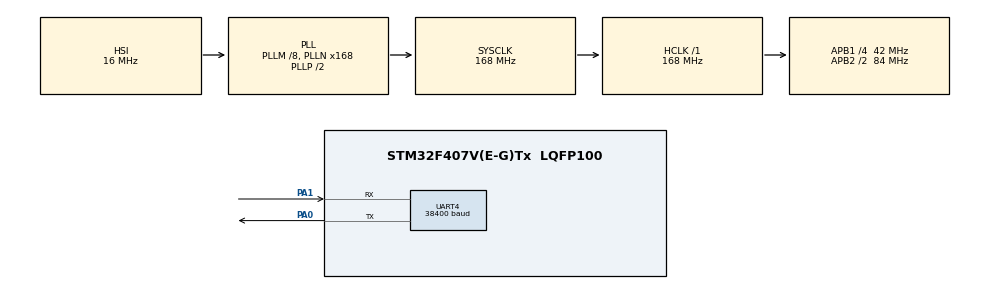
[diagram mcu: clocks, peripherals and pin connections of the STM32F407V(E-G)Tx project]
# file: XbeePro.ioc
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Mcu.Family=STM32F4
Mcu.Name=STM32F407V(E-G)Tx
Mcu.Package=LQFP100
NVIC.PriorityGroup=NVIC_PRIORITYGROUP_4
NVIC.UART4_IRQn=true\:0\:0\:false\:false\:true\:true\:true
PA0-WKUP.Mode=Asynchronous
PA0-WKUP.Signal=UART4_TX
PA1.Mode=Asynchronous
PA1.Signal=UART4_RX
PH0-OSC_IN.Mode=HSE-External-Oscillator
PH0-OSC_IN.Signal=RCC_OSC_IN
PH1-OSC_OUT.Mode=HSE-External-Oscillator
PH1-OSC_OUT.Signal=RCC_OSC_OUT
ProjectManager.HeapSize=0x200
ProjectManager.StackSize=0x400
ProjectManager.TargetToolchain=STM32CubeIDE
RCC.48MHZClocksFreq_Value=84000000
RCC.AHBFreq_Value=168000000
RCC.APB1CLKDivider=RCC_HCLK_DIV4
RCC.APB1Freq_Value=42000000
RCC.APB1TimFreq_Value=84000000
RCC.APB2CLKDivider=RCC_HCLK_DIV2
RCC.APB2Freq_Value=84000000
RCC.APB2TimFreq_Value=168000000
RCC.CortexFreq_Value=168000000
RCC.HCLKFreq_Value=168000000
RCC.HSE_VALUE=25000000
RCC.HSI_VALUE=16000000
RCC.LSE_VALUE=32768
RCC.PLLM=8
RCC.PLLN=168
RCC.SYSCLKFreq_VALUE=168000000
RCC.SYSCLKSource=RCC_SYSCLKSOURCE_PLLCLK
RCC.VCOOutputFreq_Value=336000000
UART4.BaudRate=38400
UART4.VirtualMode=Asynchronous
board=custom

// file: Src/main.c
/* USER CODE BEGIN Header */
/**
  ******************************************************************************
  * @file           : main.c
  * @brief          : Main program body
  ******************************************************************************
  * @attention
  *
  * <h2><center>&copy; Copyright (c) 2021 STMicroelectronics.
  * All rights reserved.</center></h2>
  *
  * This software component is licensed by ST under BSD 3-Clause license,
  * the "License"; You may not use this file except in compliance with the
  * License. You may obtain a copy of the License at:
  *                        opensource.org/licenses/BSD-3-Clause
  *
  ******************************************************************************
  */
/* USER CODE END Header */

#include "main.h"

/* USER CODE BEGIN Includes */
#include "stdbool.h"
#include "Xbee_Init.h"

/* USER CODE END Includes */

/* USER CODE BEGIN PTD */
#define maxSize  100

char XbeeTransmitDatas[100];
uint8_t XbeeReceive[maxSize];

int transmitDataLength=0;

bool XbeeInitFlag=0;
bool XbeeMessageCame=0;
/* USER CODE END PTD */

/* USER CODE BEGIN PD */

void sendMessageviaXbee(char *message);
int takeSize(char *Array);

/* USER CODE END PD */

UART_HandleTypeDef huart4;

void SystemClock_Config(void);
static void MX_GPIO_Init(void);
static void MX_UART4_Init(void);

/* USER CODE BEGIN 0 */

void UART4_IRQHandler(void)
{
  /* USER CODE BEGIN UART4_IRQn 0 */
  XbeeMessageCame=1;
  /* USER CODE END UART4_IRQn 0 */
  HAL_UART_IRQHandler(&huart4);
  /* USER CODE BEGIN UART4_IRQn 1 */

  /* USER CODE END UART4_IRQn 1 */
}

void sendMessageviaXbee(char *message)
{
	HAL_UART_Transmit(&huart4, (uint8_t *)message, takeSize(message),500);

}

int takeSize(char *Array)
{
    int count=0;
    while(Array[count]!='\n' && count<100)
    {
    	count++;

    }

    return (count+1);

}
/* USER CODE END 0 */

int main(void)
{

  /* MCU Configuration--------------------------------------------------------*/

  /* Reset of all peripherals, Initializes the Flash interface and the Systick. */
  HAL_Init();

  /* Configure the system clock */
  SystemClock_Config();

  /* Initialize all configured peripherals */
  MX_GPIO_Init();
  MX_UART4_Init();
  /* USER CODE BEGIN 2 */

  XbeeInitFlag=XbeeInit("1071","AAAA", "BBBB", "5" , "40");
  //(ID,SourceAddress,DestinationAddress,BaudRate,maxPacketSize)

  HAL_UART_Receive_IT(&huart4, (uint8_t *)XbeeReceive, maxSize);

  /* USER CODE END 2 */

  /* Infinite loop */
  while (1)
  {

    /* USER CODE BEGIN 3 */

	if(XbeeMessageCame)
	{
		  //You can see message received from Xbee here.
		  XbeeMessageCame=0;
		  HAL_UART_Receive_IT(&huart4, (uint8_t *)XbeeReceive, maxSize);

	}

	sprintf(XbeeTransmitDatas," Test Xbee Pro ");
	sendMessageviaXbee(XbeeTransmitDatas);
  }
  /* USER CODE END 3 */
}

void SystemClock_Config(void)
{
  RCC_OscInitTypeDef RCC_OscInitStruct = {0};
  RCC_ClkInitTypeDef RCC_ClkInitStruct = {0};

  /** Configure the main internal regulator output voltage
  */
  __HAL_RCC_PWR_CLK_ENABLE();
  __HAL_PWR_VOLTAGESCALING_CONFIG(PWR_REGULATOR_VOLTAGE_SCALE1);
  /** Initializes the CPU, AHB and APB busses clocks
  */
  RCC_OscInitStruct.OscillatorType = RCC_OSCILLATORTYPE_HSI;
  RCC_OscInitStruct.HSIState = RCC_HSI_ON;
  RCC_OscInitStruct.HSICalibrationValue = RCC_HSICALIBRATION_DEFAULT;
  RCC_OscInitStruct.PLL.PLLState = RCC_PLL_ON;
  RCC_OscInitStruct.PLL.PLLSource = RCC_PLLSOURCE_HSI;
  RCC_OscInitStruct.PLL.PLLM = 8;
  RCC_OscInitStruct.PLL.PLLN = 168;
  RCC_OscInitStruct.PLL.PLLP = RCC_PLLP_DIV2;
  RCC_OscInitStruct.PLL.PLLQ = 4;
  if (HAL_RCC_OscConfig(&RCC_OscInitStruct) != HAL_OK)
  {
    Error_Handler();
  }
  /** Initializes the CPU, AHB and APB busses clocks
  */
  RCC_ClkInitStruct.ClockType = RCC_CLOCKTYPE_HCLK|RCC_CLOCKTYPE_SYSCLK
                              |RCC_CLOCKTYPE_PCLK1|RCC_CLOCKTYPE_PCLK2;
  RCC_ClkInitStruct.SYSCLKSource = RCC_SYSCLKSOURCE_PLLCLK;
  RCC_ClkInitStruct.AHBCLKDivider = RCC_SYSCLK_DIV1;
  RCC_ClkInitStruct.APB1CLKDivider = RCC_HCLK_DIV4;
  RCC_ClkInitStruct.APB2CLKDivider = RCC_HCLK_DIV2;

  if (HAL_RCC_ClockConfig(&RCC_ClkInitStruct, FLASH_LATENCY_5) != HAL_OK)
  {
    Error_Handler();
  }
}

static void MX_UART4_Init(void)
{

  huart4.Instance = UART4;
  huart4.Init.BaudRate = 38400;
  huart4.Init.WordLength = UART_WORDLENGTH_8B;
  huart4.Init.StopBits = UART_STOPBITS_1;
  huart4.Init.Parity = UART_PARITY_NONE;
  huart4.Init.Mode = UART_MODE_TX_RX;
  huart4.Init.HwFlowCtl = UART_HWCONTROL_NONE;
  huart4.Init.OverSampling = UART_OVERSAMPLING_16;
  if (HAL_UART_Init(&huart4) != HAL_OK)
  {
    Error_Handler();
  }

}

static void MX_GPIO_Init(void)
{

  /* GPIO Ports Clock Enable */
  __HAL_RCC_GPIOH_CLK_ENABLE();
  __HAL_RCC_GPIOA_CLK_ENABLE();

}

void Error_Handler(void)
{
}

/************************ (C) COPYRIGHT STMicroelectronics *****END OF FILE****/
